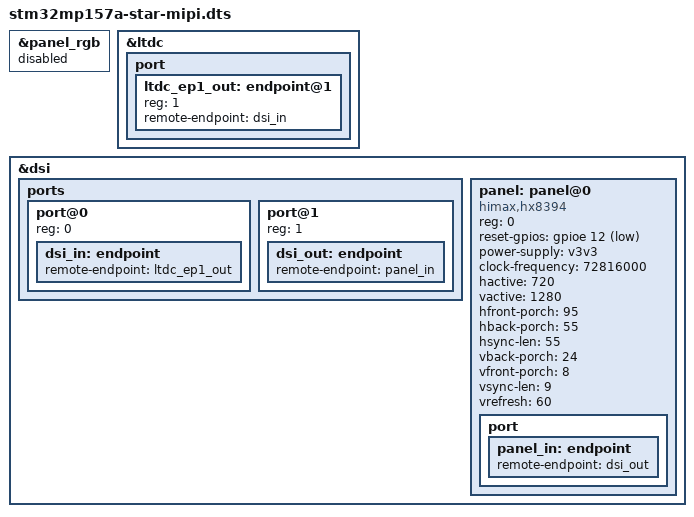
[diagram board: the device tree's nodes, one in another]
// SPDX-License-Identifier: (GPL-2.0+ OR BSD-3-Clause)
/*
 * Copyright (C) STMicroelectronics 2018 - All Rights Reserved
 * Author: Alexandre Torgue <alexandre.torgue@st.com>.
 */

/dts-v1/;

#include "stm32mp157a-star.dts"

&panel_rgb {
	status = "disabled";
	/delete-node/ port;
};

&ltdc {
	status = "okay";

	port {
		#address-cells = <1>;
		#size-cells = <0>;

		ltdc_ep1_out: endpoint@1 {
			reg = <1>;
			remote-endpoint = <&dsi_in>;
		};
	};
};

&dsi {
	#address-cells = <1>;
	#size-cells = <0>;
	status = "okay";

	ports {
		#address-cells = <1>;
		#size-cells = <0>;

		port@0 {
			reg = <0>;
			dsi_in: endpoint {
				remote-endpoint = <&ltdc_ep1_out>;
			};
		};

		port@1 {
			reg = <1>;
			dsi_out: endpoint {
				remote-endpoint = <&panel_in>;
			};
		};
	};

	panel: panel@0 {
		compatible = "himax,hx8394";
		reg = <0>;
		reset-gpios = <&gpioe 12 GPIO_ACTIVE_LOW>;
		power-supply = <&v3v3>;

		clock-frequency = <72816000>;
		hactive = <720>;
		vactive = <1280>;
		hfront-porch = <95>;
		hback-porch = <55>;
		hsync-len = <55>;
		vback-porch = <24>;
		vfront-porch = <8>;
		vsync-len = <9>;	
		vrefresh = <60>;

		status = "okay";

		port {
			panel_in: endpoint {
				remote-endpoint = <&dsi_out>;
			};
		};
	};

};
